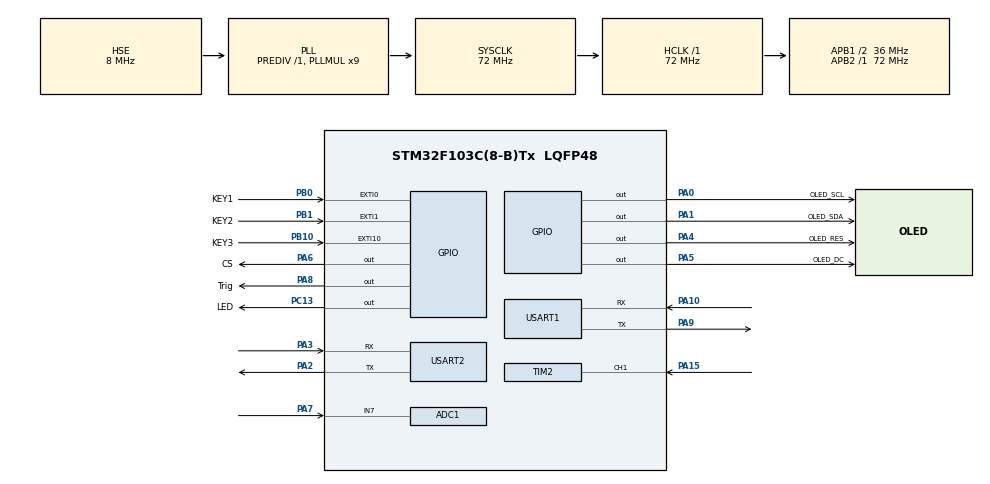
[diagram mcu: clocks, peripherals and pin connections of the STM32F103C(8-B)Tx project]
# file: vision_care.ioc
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ADC1.Channel-3\#ChannelRegularConversion=ADC_CHANNEL_7
ADC1.NbrOfConversionFlag=1
ADC1.Rank-3\#ChannelRegularConversion=1
ADC1.SamplingTime-3\#ChannelRegularConversion=ADC_SAMPLETIME_1CYCLE_5
ADC1.master=1
Dma.Request0=USART1_RX
Dma.USART1_RX.0.Direction=DMA_PERIPH_TO_MEMORY
Dma.USART1_RX.0.Instance=DMA1_Channel5
Dma.USART1_RX.0.MemDataAlignment=DMA_MDATAALIGN_BYTE
Dma.USART1_RX.0.MemInc=DMA_MINC_ENABLE
Dma.USART1_RX.0.Mode=DMA_NORMAL
Dma.USART1_RX.0.PeriphDataAlignment=DMA_PDATAALIGN_BYTE
Dma.USART1_RX.0.PeriphInc=DMA_PINC_DISABLE
Dma.USART1_RX.0.Priority=DMA_PRIORITY_LOW
Mcu.Family=STM32F1
Mcu.Name=STM32F103C(8-B)Tx
Mcu.Package=LQFP48
NVIC.DMA1_Channel5_IRQn=true\:0\:0\:false\:false\:true\:false\:true\:true
NVIC.EXTI0_IRQn=true\:0\:0\:false\:false\:true\:true\:true\:true
NVIC.EXTI15_10_IRQn=true\:0\:0\:false\:false\:true\:true\:true\:true
NVIC.EXTI1_IRQn=true\:0\:0\:false\:false\:true\:true\:true\:true
NVIC.PriorityGroup=NVIC_PRIORITYGROUP_4
NVIC.RTC_IRQn=true\:0\:0\:false\:false\:true\:true\:true\:true
NVIC.TIM2_IRQn=true\:0\:0\:false\:false\:true\:true\:true\:true
NVIC.USART1_IRQn=true\:0\:0\:false\:false\:true\:true\:true\:true
PA0-WKUP.GPIO_Label=OLED_SCL
PA0-WKUP.GPIO_ModeDefaultOutputPP=GPIO_MODE_OUTPUT_PP
PA0-WKUP.GPIO_PuPd=GPIO_PULLUP
PA0-WKUP.GPIO_Speed=GPIO_SPEED_FREQ_HIGH
PA0-WKUP.PinState=GPIO_PIN_SET
PA0-WKUP.Signal=GPIO_Output
PA1.GPIO_Label=OLED_SDA
PA1.GPIO_ModeDefaultOutputPP=GPIO_MODE_OUTPUT_PP
PA1.GPIO_PuPd=GPIO_PULLUP
PA1.GPIO_Speed=GPIO_SPEED_FREQ_HIGH
PA1.PinState=GPIO_PIN_SET
PA1.Signal=GPIO_Output
PA10.Mode=Asynchronous
PA10.Signal=USART1_RX
PA13.Mode=Serial_Wire
PA13.Signal=SYS_JTMS-SWDIO
PA14.Mode=Serial_Wire
PA14.Signal=SYS_JTCK-SWCLK
PA15.Signal=S_TIM2_CH1_ETR
PA2.Mode=Asynchronous
PA2.Signal=USART2_TX
PA3.Mode=Asynchronous
PA3.Signal=USART2_RX
PA4.GPIO_Label=OLED_RES
PA4.GPIO_ModeDefaultOutputPP=GPIO_MODE_OUTPUT_PP
PA4.GPIO_PuPd=GPIO_PULLUP
PA4.GPIO_Speed=GPIO_SPEED_FREQ_HIGH
PA4.PinState=GPIO_PIN_SET
PA4.Signal=GPIO_Output
PA5.GPIO_Label=OLED_DC
PA5.GPIO_PuPd=GPIO_PULLUP
PA5.GPIO_Speed=GPIO_SPEED_FREQ_HIGH
PA5.PinState=GPIO_PIN_SET
PA5.Signal=GPIO_Output
PA6.GPIO_Label=CS
PA6.GPIO_PuPd=GPIO_PULLUP
PA6.GPIO_Speed=GPIO_SPEED_FREQ_HIGH
PA6.PinState=GPIO_PIN_SET
PA6.Signal=GPIO_Output
PA7.Signal=ADCx_IN7
PA8.GPIO_Label=Trig
PA8.GPIO_PuPd=GPIO_PULLUP
PA8.GPIO_Speed=GPIO_SPEED_FREQ_HIGH
PA8.Signal=GPIO_Output
PA9.Mode=Asynchronous
PA9.Signal=USART1_TX
PB0.GPIO_Label=KEY1
PB0.GPIO_ModeDefaultEXTI=GPIO_MODE_IT_FALLING
PB0.GPIO_PuPd=GPIO_PULLUP
PB0.Signal=GPXTI0
PB1.GPIO_Label=KEY2
PB1.GPIO_ModeDefaultEXTI=GPIO_MODE_IT_FALLING
PB1.GPIO_PuPd=GPIO_PULLUP
PB1.Signal=GPXTI1
PB10.GPIO_Label=KEY3
PB10.GPIO_ModeDefaultEXTI=GPIO_MODE_IT_FALLING
PB10.GPIO_PuPd=GPIO_PULLUP
PB10.Signal=GPXTI10
PC13-TAMPER-RTC.GPIO_Label=LED
PC13-TAMPER-RTC.GPIO_ModeDefaultOutputPP=GPIO_MODE_OUTPUT_PP
PC13-TAMPER-RTC.GPIO_PuPd=GPIO_PULLUP
PC13-TAMPER-RTC.GPIO_Speed=GPIO_SPEED_FREQ_MEDIUM
PC13-TAMPER-RTC.PinState=GPIO_PIN_SET
PC13-TAMPER-RTC.Signal=GPIO_Output
PD0-OSC_IN.Mode=HSE-External-Oscillator
PD0-OSC_IN.Signal=RCC_OSC_IN
PD1-OSC_OUT.Mode=HSE-External-Oscillator
PD1-OSC_OUT.Signal=RCC_OSC_OUT
ProjectManager.HeapSize=0x200
ProjectManager.StackSize=0x400
ProjectManager.TargetToolchain=MDK-ARM V5.32
RCC.ADCPresc=RCC_ADCPCLK2_DIV6
RCC.AHBFreq_Value=72000000
RCC.APB1CLKDivider=RCC_HCLK_DIV2
RCC.APB1Freq_Value=36000000
RCC.APB1TimFreq_Value=72000000
RCC.APB2Freq_Value=72000000
RCC.APB2TimFreq_Value=72000000
RCC.HCLKFreq_Value=72000000
RCC.PLLMUL=RCC_PLL_MUL9
RCC.PLLSourceVirtual=RCC_PLLSOURCE_HSE
RCC.SYSCLKFreq_VALUE=72000000
RCC.SYSCLKSource=RCC_SYSCLKSOURCE_PLLCLK
RCC.USBFreq_Value=72000000
RTC.Date=29
RTC.Hours=20
RTC.Minutes=25
RTC.Year=24
SH.ADCx_IN7.0=ADC1_IN7,IN7
SH.S_TIM2_CH1_ETR.0=TIM2_CH1,Input_Capture1_from_TI1
TIM2.AutoReloadPreload=TIM_AUTORELOAD_PRELOAD_ENABLE
TIM2.Channel-Input_Capture1_from_TI1=TIM_CHANNEL_1
TIM2.Prescaler=71
USART1.VirtualMode=VM_ASYNC
USART2.VirtualMode=VM_ASYNC
VP_RTC_No_RTC_Output.Mode=RTC_OUT_NO
VP_RTC_VS_RTC_Activate.Mode=RTC_Enabled
VP_RTC_VS_RTC_Calendar.Mode=RTC_Calendar
VP_TIM2_VS_ClockSourceINT.Mode=Internal
board=custom

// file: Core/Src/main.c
/* USER CODE BEGIN Header */
/**
  ******************************************************************************
  * @file           : main.c
  * @brief          : Main program body
  ******************************************************************************
  * @attention
  *
  * Copyright (c) 2024 STMicroelectronics.
  * All rights reserved.
  *
  * This software is licensed under terms that can be found in the LICENSE file
  * in the root directory of this software component.
  * If no LICENSE file comes with this software, it is provided AS-IS.
  *
  ******************************************************************************
  */
/* USER CODE END Header */
#include "main.h"
#include "adc.h"
#include "dma.h"
#include "rtc.h"
#include "tim.h"
#include "usart.h"
#include "gpio.h"

/* USER CODE BEGIN Includes */
#include "stdio.h"
#include "test.h"
#include "ecb02.h"
#include "oled.h"
#include "sr04.h"
#include "ui_home.h"
#include "ui_setting.h"
/* USER CODE END Includes */

void SystemClock_Config(void);

int main(void)
{

  /* MCU Configuration--------------------------------------------------------*/

  /* Reset of all peripherals, Initializes the Flash interface and the Systick. */
  HAL_Init();

  /* Configure the system clock */
  SystemClock_Config();

  /* Initialize all configured peripherals */
  MX_GPIO_Init();
  MX_DMA_Init();
  MX_USART1_UART_Init();
  MX_TIM2_Init();
  MX_RTC_Init();
  MX_ADC1_Init();
  MX_USART2_UART_Init();
  /* USER CODE BEGIN 2 */
	OLED_Init();
	OLED_ColorTurn(0);//0������ʾ��1 ��ɫ��ʾ
  OLED_DisplayTurn(0);//0������ʾ 1 ��Ļ��ת��ʾ
	OLED_Clear();
  /* USER CODE END 2 */

  /* Infinite loop */
  while (1)
  {

    /* USER CODE BEGIN 3 */
		ui_home();

		//ui_setting();

  }
  /* USER CODE END 3 */
}

void SystemClock_Config(void)
{
  RCC_OscInitTypeDef RCC_OscInitStruct = {0};
  RCC_ClkInitTypeDef RCC_ClkInitStruct = {0};
  RCC_PeriphCLKInitTypeDef PeriphClkInit = {0};

  /** Initializes the RCC Oscillators according to the specified parameters
  * in the RCC_OscInitTypeDef structure.
  */
  RCC_OscInitStruct.OscillatorType = RCC_OSCILLATORTYPE_LSI|RCC_OSCILLATORTYPE_HSE;
  RCC_OscInitStruct.HSEState = RCC_HSE_ON;
  RCC_OscInitStruct.HSEPredivValue = RCC_HSE_PREDIV_DIV1;
  RCC_OscInitStruct.HSIState = RCC_HSI_ON;
  RCC_OscInitStruct.LSIState = RCC_LSI_ON;
  RCC_OscInitStruct.PLL.PLLState = RCC_PLL_ON;
  RCC_OscInitStruct.PLL.PLLSource = RCC_PLLSOURCE_HSE;
  RCC_OscInitStruct.PLL.PLLMUL = RCC_PLL_MUL9;
  if (HAL_RCC_OscConfig(&RCC_OscInitStruct) != HAL_OK)
  {
    Error_Handler();
  }

  /** Initializes the CPU, AHB and APB buses clocks
  */
  RCC_ClkInitStruct.ClockType = RCC_CLOCKTYPE_HCLK|RCC_CLOCKTYPE_SYSCLK
                              |RCC_CLOCKTYPE_PCLK1|RCC_CLOCKTYPE_PCLK2;
  RCC_ClkInitStruct.SYSCLKSource = RCC_SYSCLKSOURCE_PLLCLK;
  RCC_ClkInitStruct.AHBCLKDivider = RCC_SYSCLK_DIV1;
  RCC_ClkInitStruct.APB1CLKDivider = RCC_HCLK_DIV2;
  RCC_ClkInitStruct.APB2CLKDivider = RCC_HCLK_DIV1;

  if (HAL_RCC_ClockConfig(&RCC_ClkInitStruct, FLASH_LATENCY_2) != HAL_OK)
  {
    Error_Handler();
  }
  PeriphClkInit.PeriphClockSelection = RCC_PERIPHCLK_RTC|RCC_PERIPHCLK_ADC;
  PeriphClkInit.RTCClockSelection = RCC_RTCCLKSOURCE_LSI;
  PeriphClkInit.AdcClockSelection = RCC_ADCPCLK2_DIV6;
  if (HAL_RCCEx_PeriphCLKConfig(&PeriphClkInit) != HAL_OK)
  {
    Error_Handler();
  }
}

void Error_Handler(void)
{
  __disable_irq();
  while (1)
  {
  }
}
